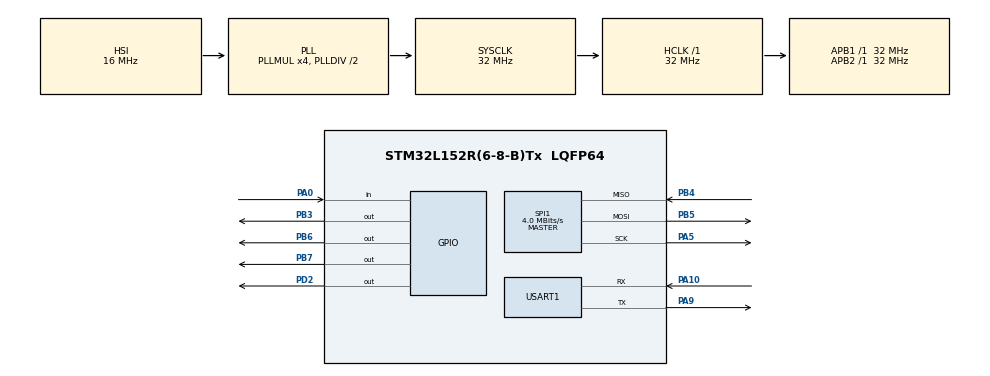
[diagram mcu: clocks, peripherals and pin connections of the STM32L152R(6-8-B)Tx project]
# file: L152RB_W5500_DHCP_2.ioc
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Mcu.Family=STM32L1
Mcu.Name=STM32L152R(6-8-B)Tx
Mcu.Package=LQFP64
NVIC.PriorityGroup=NVIC_PRIORITYGROUP_4
NVIC.SPI1_IRQn=true\:0\:0\:false\:false\:true\:true\:true
NVIC.USART1_IRQn=true\:0\:0\:false\:false\:true\:true\:true
PA0-WKUP1.Signal=GPIO_Input
PA10.Mode=Asynchronous
PA10.Signal=USART1_RX
PA5.Mode=Full_Duplex_Master
PA5.Signal=SPI1_SCK
PA9.Mode=Asynchronous
PA9.Signal=USART1_TX
PB3.Signal=GPIO_Output
PB4.Mode=Full_Duplex_Master
PB4.Signal=SPI1_MISO
PB5.Mode=Full_Duplex_Master
PB5.Signal=SPI1_MOSI
PB6.Signal=GPIO_Output
PB7.Signal=GPIO_Output
PD2.GPIO_Speed=GPIO_SPEED_FREQ_VERY_HIGH
PD2.PinState=GPIO_PIN_SET
PD2.Signal=GPIO_Output
ProjectManager.HeapSize=0x200
ProjectManager.StackSize=0x400
ProjectManager.TargetToolchain=STM32CubeIDE
RCC.48MHZClocksFreq_Value=32000000
RCC.AHBFreq_Value=32000000
RCC.APB1Freq_Value=32000000
RCC.APB1TimFreq_Value=32000000
RCC.APB2Freq_Value=32000000
RCC.APB2TimFreq_Value=32000000
RCC.HCLKFreq_Value=32000000
RCC.HSE_VALUE=24000000
RCC.HSI_VALUE=16000000
RCC.LSE_VALUE=32768
RCC.MSI_VALUE=2097000
RCC.PLLMUL=RCC_PLL_MUL4
RCC.SYSCLKFreq_VALUE=32000000
RCC.SYSCLKSource=RCC_SYSCLKSOURCE_PLLCLK
RCC.VCOOutputFreq_Value=64000000
SPI1.BaudRatePrescaler=SPI_BAUDRATEPRESCALER_8
SPI1.CalculateBaudRate=4.0 MBits/s
SPI1.Direction=SPI_DIRECTION_2LINES
SPI1.Mode=SPI_MODE_MASTER
SPI1.VirtualType=VM_MASTER
USART1.VirtualMode=VM_ASYNC
board=custom

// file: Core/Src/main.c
/* USER CODE BEGIN Header */
/**
  ******************************************************************************
  * @file           : main.c
  * @brief          : Main program body
  ******************************************************************************
  * @attention
  *
  * <h2><center>&copy; Copyright (c) 2020 STMicroelectronics.
  * All rights reserved.</center></h2>
  *
  * This software component is licensed by ST under BSD 3-Clause license,
  * the "License"; You may not use this file except in compliance with the
  * License. You may obtain a copy of the License at:
  *                        opensource.org/licenses/BSD-3-Clause
  *
  ******************************************************************************
  */
/* USER CODE END Header */
#include "main.h"
#include "w5500.h"
#include "socket.h"
#include "http_client.h"
#include <stdio.h>
/* USER CODE BEGIN Includes */
static uint16_t toggle = 0;
/* USER CODE END Includes */

SPI_HandleTypeDef hspi1;

UART_HandleTypeDef huart1;

void SystemClock_Config(void);
static void MX_GPIO_Init(void);
static void MX_SPI1_Init(void);
static void MX_USART1_UART_Init(void);
int __io_putchar (int ch) {
	uint8_t c = ch;
	HAL_UART_Transmit(&huart1, &c, 1, 100);
	//HAL_UART_Transmit_IT(&huart1, (uint8_t*)&UART1_TxBuffer, countof(UART1_TxBuffer)-1);
	return ch;
}
//int _write(int file, char* p, int len)
//{
//  HAL_UART_Transmit(&huart1, p, len, 10);
//  return len;
//}

int main(void)
{

  /* MCU Configuration--------------------------------------------------------*/

  /* Reset of all peripherals, Initializes the Flash interface and the Systick. */
  HAL_Init();

  /* Configure the system clock */
  SystemClock_Config();

  /* Initialize all configured peripherals */
  MX_GPIO_Init();
  MX_SPI1_Init();
  MX_USART1_UART_Init();
  printf("\r\nPower On\r\n");
  printf("Compiled: " __DATE__ " " __TIME__ "\r\n");

  printf("SPI2->CR1: %04X\r\n", (uint16_t) SPI1->CR1);
  printf("SPI2->CR2: %04X\r\n", (uint16_t) SPI1->CR2);

  W5500_Init();

  printf("Press Blue User Button.\r\n");
  /* Infinite loop */
  while (1)
  {
      if (HAL_GPIO_ReadPin(GPIOA,GPIO_PIN_0) == GPIO_PIN_SET)
      {
    	  HAL_GPIO_TogglePin(GPIOB, GPIO_PIN_6);
    	  HAL_GPIO_TogglePin(GPIOB, GPIO_PIN_7);
          toggle = 1 - toggle;
          http_client_request(toggle);
      }
      //HAL_Delay(10);
  }
}

void SystemClock_Config(void)
{
  RCC_OscInitTypeDef RCC_OscInitStruct = {0};
  RCC_ClkInitTypeDef RCC_ClkInitStruct = {0};

  /** Configure the main internal regulator output voltage
  */
  __HAL_PWR_VOLTAGESCALING_CONFIG(PWR_REGULATOR_VOLTAGE_SCALE1);
  /** Initializes the RCC Oscillators according to the specified parameters
  * in the RCC_OscInitTypeDef structure.
  */
  RCC_OscInitStruct.OscillatorType = RCC_OSCILLATORTYPE_HSI;
  RCC_OscInitStruct.HSIState = RCC_HSI_ON;
  RCC_OscInitStruct.HSICalibrationValue = RCC_HSICALIBRATION_DEFAULT;
  RCC_OscInitStruct.PLL.PLLState = RCC_PLL_ON;
  RCC_OscInitStruct.PLL.PLLSource = RCC_PLLSOURCE_HSI;
  RCC_OscInitStruct.PLL.PLLMUL = RCC_PLL_MUL4;
  RCC_OscInitStruct.PLL.PLLDIV = RCC_PLL_DIV2;
  if (HAL_RCC_OscConfig(&RCC_OscInitStruct) != HAL_OK)
  {
    Error_Handler();
  }
  /** Initializes the CPU, AHB and APB buses clocks
  */
  RCC_ClkInitStruct.ClockType = RCC_CLOCKTYPE_HCLK|RCC_CLOCKTYPE_SYSCLK
                              |RCC_CLOCKTYPE_PCLK1|RCC_CLOCKTYPE_PCLK2;
  RCC_ClkInitStruct.SYSCLKSource = RCC_SYSCLKSOURCE_PLLCLK;
  RCC_ClkInitStruct.AHBCLKDivider = RCC_SYSCLK_DIV1;
  RCC_ClkInitStruct.APB1CLKDivider = RCC_HCLK_DIV1;
  RCC_ClkInitStruct.APB2CLKDivider = RCC_HCLK_DIV1;

  if (HAL_RCC_ClockConfig(&RCC_ClkInitStruct, FLASH_LATENCY_1) != HAL_OK)
  {
    Error_Handler();
  }
}

static void MX_SPI1_Init(void)
{

  /* SPI1 parameter configuration*/
  hspi1.Instance = SPI1;
  hspi1.Init.Mode = SPI_MODE_MASTER;
  hspi1.Init.Direction = SPI_DIRECTION_2LINES;
  hspi1.Init.DataSize = SPI_DATASIZE_8BIT;
  hspi1.Init.CLKPolarity = SPI_POLARITY_LOW;
  hspi1.Init.CLKPhase = SPI_PHASE_1EDGE;
  hspi1.Init.NSS = SPI_NSS_SOFT;
  hspi1.Init.BaudRatePrescaler = SPI_BAUDRATEPRESCALER_8;
  hspi1.Init.FirstBit = SPI_FIRSTBIT_MSB;
  hspi1.Init.TIMode = SPI_TIMODE_DISABLE;
  hspi1.Init.CRCCalculation = SPI_CRCCALCULATION_DISABLE;
  hspi1.Init.CRCPolynomial = 10;
  if (HAL_SPI_Init(&hspi1) != HAL_OK)
  {
    Error_Handler();
  }

}

static void MX_USART1_UART_Init(void)
{

  huart1.Instance = USART1;
  huart1.Init.BaudRate = 115200;
  huart1.Init.WordLength = UART_WORDLENGTH_8B;
  huart1.Init.StopBits = UART_STOPBITS_1;
  huart1.Init.Parity = UART_PARITY_NONE;
  huart1.Init.Mode = UART_MODE_TX_RX;
  huart1.Init.HwFlowCtl = UART_HWCONTROL_NONE;
  huart1.Init.OverSampling = UART_OVERSAMPLING_16;
  if (HAL_UART_Init(&huart1) != HAL_OK)
  {
    Error_Handler();
  }

}

static void MX_GPIO_Init(void)
{
  GPIO_InitTypeDef GPIO_InitStruct = {0};

  /* GPIO Ports Clock Enable */
  __HAL_RCC_GPIOA_CLK_ENABLE();
  __HAL_RCC_GPIOD_CLK_ENABLE();
  __HAL_RCC_GPIOB_CLK_ENABLE();

  /*Configure GPIO pin Output Level */
  HAL_GPIO_WritePin(GPIOD, GPIO_PIN_2, GPIO_PIN_SET);

  /*Configure GPIO pin Output Level */
  HAL_GPIO_WritePin(GPIOB, GPIO_PIN_3|GPIO_PIN_6|GPIO_PIN_7, GPIO_PIN_RESET);

  /*Configure GPIO pin : PA0 */
  GPIO_InitStruct.Pin = GPIO_PIN_0;
  GPIO_InitStruct.Mode = GPIO_MODE_INPUT;
  GPIO_InitStruct.Pull = GPIO_NOPULL;
  HAL_GPIO_Init(GPIOA, &GPIO_InitStruct);

  /*Configure GPIO pin : PD2 */
  GPIO_InitStruct.Pin = GPIO_PIN_2;
  GPIO_InitStruct.Mode = GPIO_MODE_OUTPUT_PP;
  GPIO_InitStruct.Pull = GPIO_NOPULL;
  GPIO_InitStruct.Speed = GPIO_SPEED_FREQ_VERY_HIGH;
  HAL_GPIO_Init(GPIOD, &GPIO_InitStruct);

  /*Configure GPIO pins : PB3 PB6 PB7 */
  GPIO_InitStruct.Pin = GPIO_PIN_3|GPIO_PIN_6|GPIO_PIN_7;
  GPIO_InitStruct.Mode = GPIO_MODE_OUTPUT_PP;
  GPIO_InitStruct.Pull = GPIO_NOPULL;
  GPIO_InitStruct.Speed = GPIO_SPEED_FREQ_LOW;
  HAL_GPIO_Init(GPIOB, &GPIO_InitStruct);

}

void Error_Handler(void)
{
}

/************************ (C) COPYRIGHT STMicroelectronics *****END OF FILE****/
